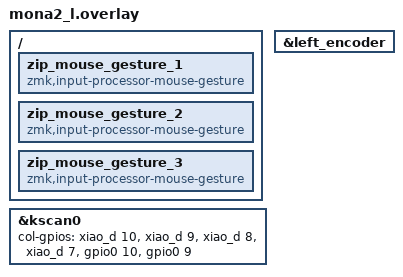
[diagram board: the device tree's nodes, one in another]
#include "mona2.dtsi"

&kscan0 {
        col-gpios
            = <&xiao_d 10 GPIO_ACTIVE_HIGH>
            , <&xiao_d 9 GPIO_ACTIVE_HIGH> 
            , <&xiao_d 8 GPIO_ACTIVE_HIGH> 
            , <&xiao_d 7 GPIO_ACTIVE_HIGH> 
            , <&gpio0 10 GPIO_ACTIVE_HIGH>
            , <&gpio0 9 GPIO_ACTIVE_HIGH>
            ;
};

&left_encoder {
    status = "okay";
};
/* mona2_l.overlay の一番下にこれを追加 */
/ {
    zip_mouse_gesture_1: zip_mouse_gesture_1 {
        compatible = "zmk,input-processor-mouse-gesture";
    };
    zip_mouse_gesture_2: zip_mouse_gesture_2 {
        compatible = "zmk,input-processor-mouse-gesture";
    };
    zip_mouse_gesture_3: zip_mouse_gesture_3 {
        compatible = "zmk,input-processor-mouse-gesture";
    };
};
